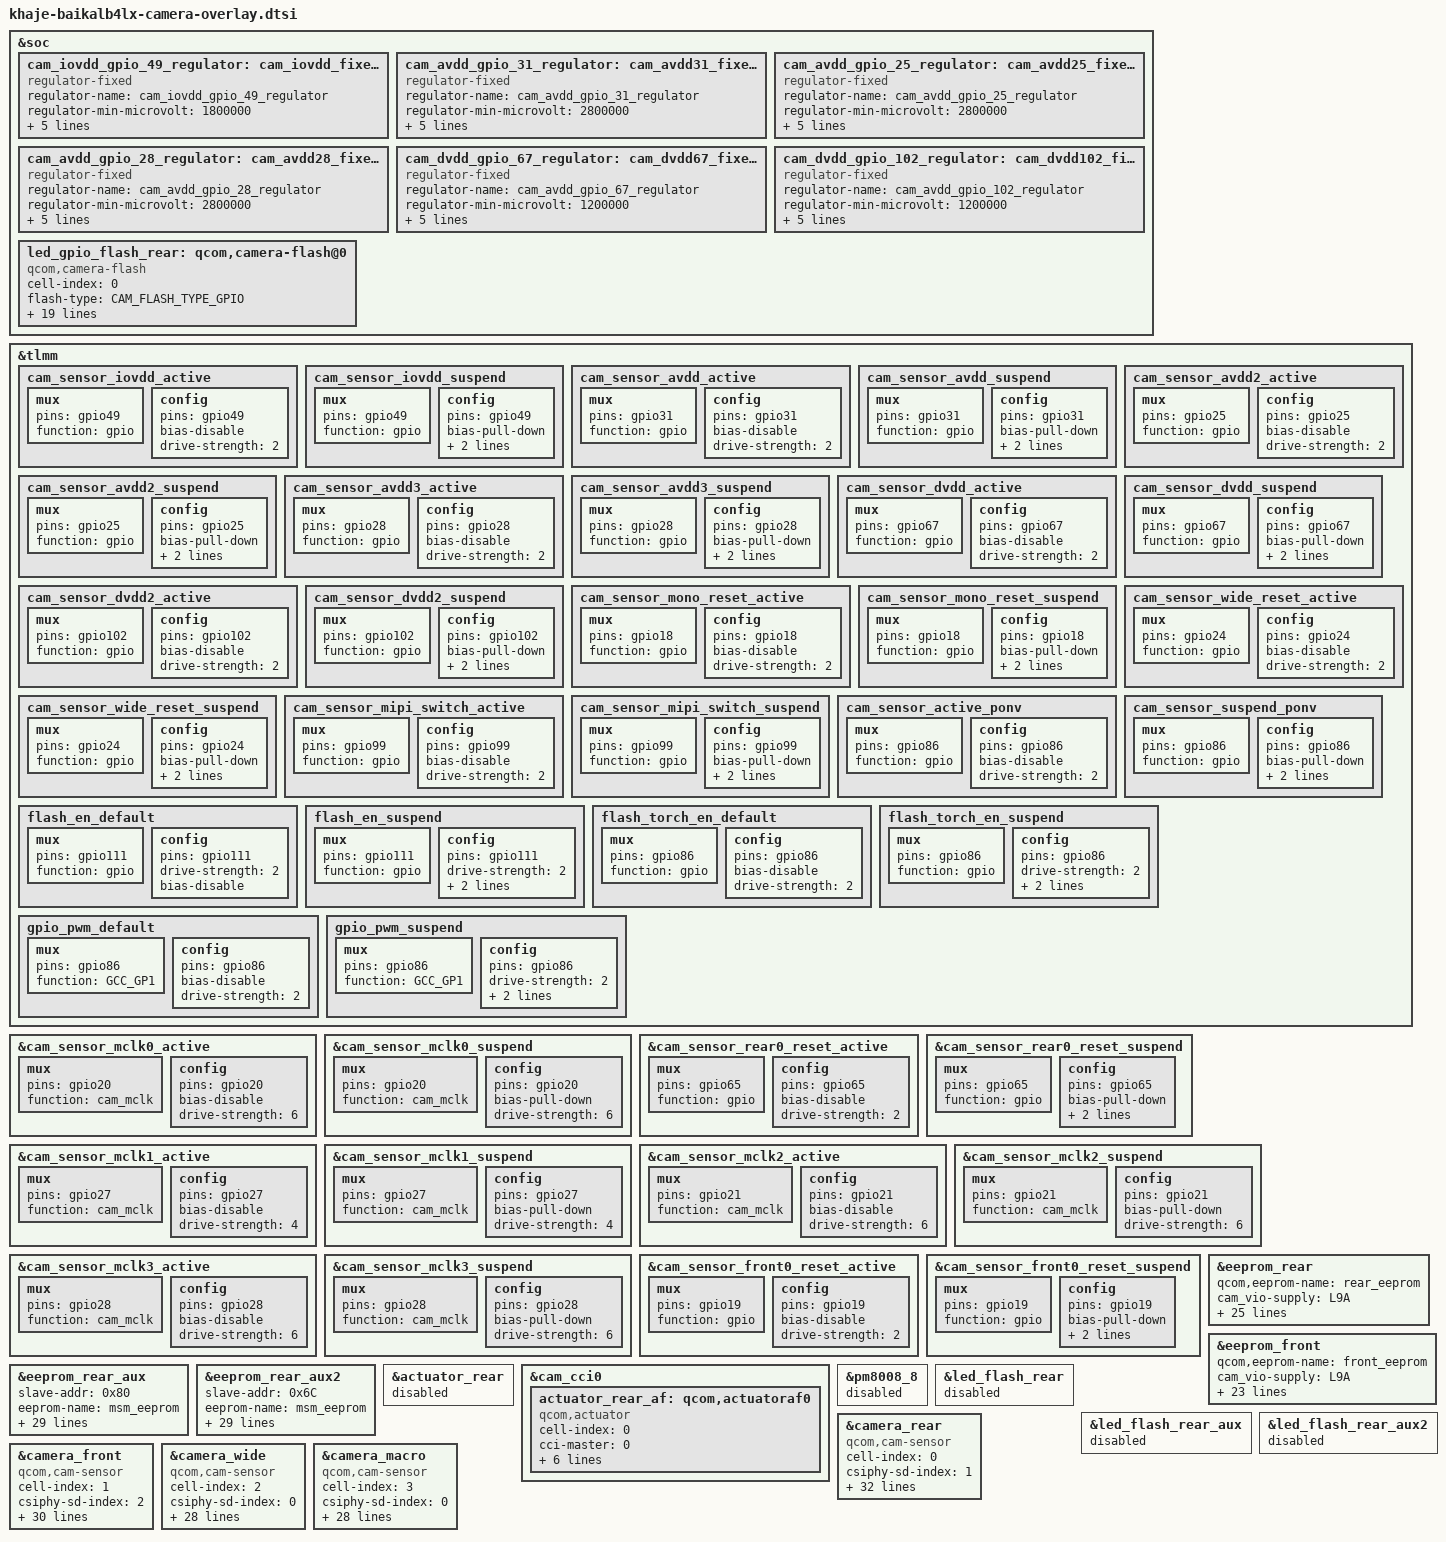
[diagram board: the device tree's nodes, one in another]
//khaje-camera-sensor-qrd.dtsi

&soc {
    cam_iovdd_gpio_49_regulator:cam_iovdd_fixed_regulator {
        compatible = "regulator-fixed";
        regulator-name = "cam_iovdd_gpio_49_regulator";
        regulator-min-microvolt = <1800000>;
        regulator-max-microvolt = <1800000>;
        enable-active-high;
        gpio = <&tlmm 49 0>;
        pinctrl-names = "cam_default","cam_suspend";
        pinctrl-0 = <&cam_sensor_iovdd_active>;
        pinctrl-1 = <&cam_sensor_iovdd_suspend>;
    };
    cam_avdd_gpio_31_regulator:cam_avdd31_fixed_regulator {
        compatible = "regulator-fixed";
        regulator-name = "cam_avdd_gpio_31_regulator";
        regulator-min-microvolt = <2800000>;
        regulator-max-microvolt = <2800000>;
        enable-active-high;
        gpio = <&tlmm 31 0>;
        pinctrl-names = "cam_default","cam_suspend";
        pinctrl-0 = <&cam_sensor_avdd_active>;
        pinctrl-1 = <&cam_sensor_avdd_suspend>;
    };
    cam_avdd_gpio_25_regulator:cam_avdd25_fixed_regulator {
        compatible = "regulator-fixed";
        regulator-name = "cam_avdd_gpio_25_regulator";
        regulator-min-microvolt = <2800000>;
        regulator-max-microvolt = <2800000>;
        enable-active-high;
        gpio = <&tlmm 25 0>;
        pinctrl-names = "cam_default","cam_suspend";
        pinctrl-0 = <&cam_sensor_avdd2_active>;
        pinctrl-1 = <&cam_sensor_avdd2_suspend>;
    };
    cam_avdd_gpio_28_regulator:cam_avdd28_fixed_regulator {
        compatible = "regulator-fixed";
        regulator-name = "cam_avdd_gpio_28_regulator";
        regulator-min-microvolt = <2800000>;
        regulator-max-microvolt = <2800000>;
        enable-active-high;
        gpio = <&tlmm 28 0>;
        pinctrl-names = "cam_default","cam_suspend";
        pinctrl-0 = <&cam_sensor_avdd3_active>;
        pinctrl-1 = <&cam_sensor_avdd3_suspend>;
    };
    cam_dvdd_gpio_67_regulator:cam_dvdd67_fixed_regulator {
        compatible = "regulator-fixed";
        regulator-name = "cam_avdd_gpio_67_regulator";
        regulator-min-microvolt = <1200000>;
        regulator-max-microvolt = <1200000>;
        enable-active-high;
        gpio = <&tlmm 67 0>;
        pinctrl-names = "cam_default","cam_suspend";
        pinctrl-0 = <&cam_sensor_dvdd_active>;
        pinctrl-1 = <&cam_sensor_dvdd_suspend>;
    };
    cam_dvdd_gpio_102_regulator:cam_dvdd102_fixed_regulator {
        compatible = "regulator-fixed";
        regulator-name = "cam_avdd_gpio_102_regulator";
        regulator-min-microvolt = <1200000>;
        regulator-max-microvolt = <1200000>;
        enable-active-high;
        gpio = <&tlmm 102 0>;
        pinctrl-names = "cam_default","cam_suspend";
        pinctrl-0 = <&cam_sensor_dvdd2_active>;
        pinctrl-1 = <&cam_sensor_dvdd2_suspend>;
    };
};

&tlmm {

    cam_sensor_iovdd_active: cam_sensor_iovdd_active {
        mux {
            pins = "gpio49";
            function = "gpio";
        };
        config {
            pins = "gpio49";
            bias-disable; /* No PULL */
            drive-strength = <2>; /* 2 MA */
        };
    };
    cam_sensor_iovdd_suspend: cam_sensor_iovdd_suspend {
        mux {
            pins = "gpio49";
            function = "gpio";
        };
        config {
            pins = "gpio49";
            bias-pull-down; /* PULL DOWN */
            drive-strength = <2>; /* 2 MA */
            output-low;
        };
    };
    cam_sensor_avdd_active: cam_sensor_avdd_active {
        mux {
            pins = "gpio31";
            function = "gpio";
        };
        config {
            pins = "gpio31";
            bias-disable; /* No PULL */
            drive-strength = <2>; /* 2 MA */
        };
    };
    cam_sensor_avdd_suspend: cam_sensor_avdd_suspend {
        mux {
            pins = "gpio31";
            function = "gpio";
        };
        config {
            pins = "gpio31";
            bias-pull-down; /* PULL DOWN */
            drive-strength = <2>; /* 2 MA */
            output-low;
        };
    };
    cam_sensor_avdd2_active: cam_sensor_avdd2_active {
        mux {
            pins = "gpio25";
            function = "gpio";
        };
        config {
            pins = "gpio25";
            bias-disable; /* No PULL */
            drive-strength = <2>; /* 2 MA */
        };
    };
    cam_sensor_avdd2_suspend: cam_sensor_avdd2_suspend {
        mux {
            pins = "gpio25";
            function = "gpio";
        };
        config {
            pins = "gpio25";
            bias-pull-down; /* PULL DOWN */
            drive-strength = <2>; /* 2 MA */
            output-low;
        };
    };
    cam_sensor_avdd3_active: cam_sensor_avdd3_active {
        mux {
            pins = "gpio28";
            function = "gpio";
        };
        config {
            pins = "gpio28";
            bias-disable; /* No PULL */
            drive-strength = <2>; /* 2 MA */
        };
    };
    cam_sensor_avdd3_suspend: cam_sensor_avdd3_suspend {
        mux {
            pins = "gpio28";
            function = "gpio";
        };
        config {
            pins = "gpio28";
            bias-pull-down; /* PULL DOWN */
            drive-strength = <2>; /* 2 MA */
            output-low;
        };
    };
    cam_sensor_dvdd_active: cam_sensor_dvdd_active {
        mux {
            pins = "gpio67";
            function = "gpio";
        };
        config {
            pins = "gpio67";
            bias-disable; /* No PULL */
            drive-strength = <2>; /* 2 MA */
        };
    };
    cam_sensor_dvdd_suspend: cam_sensor_dvdd_suspend {
        mux {
            pins = "gpio67";
            function = "gpio";
        };
        config {
            pins = "gpio67";
            bias-pull-down; /* PULL DOWN */
            drive-strength = <2>; /* 2 MA */
            output-low;
        };
    };
    cam_sensor_dvdd2_active: cam_sensor_dvdd2_active {
        mux {
            pins = "gpio102";
            function = "gpio";
        };
        config {
            pins = "gpio102";
            bias-disable; /* No PULL */
            drive-strength = <2>; /* 2 MA */
        };
    };
    cam_sensor_dvdd2_suspend: cam_sensor_dvdd2_suspend {
        mux {
            pins = "gpio102";
            function = "gpio";
        };
        config {
            pins = "gpio102";
            bias-pull-down; /* PULL DOWN */
            drive-strength = <2>; /* 2 MA */
            output-low;
        };
    };
    cam_sensor_mono_reset_active: cam_sensor_mono_reset_active {
        mux {
            pins = "gpio18";
            function = "gpio";
        };
        config {
            pins = "gpio18";
            bias-disable; /* No PULL */
            drive-strength = <2>; /* 2 MA */
        };
    };
    cam_sensor_mono_reset_suspend: cam_sensor_mono_reset_suspend {
        mux {
            pins = "gpio18";
            function = "gpio";
        };
        config {
            pins = "gpio18";
            bias-pull-down; /* PULL DOWN */
            drive-strength = <2>; /* 2 MA */
            output-low;
        };
    };

    cam_sensor_wide_reset_active: cam_sensor_wide_reset_active {
        mux {
            pins = "gpio24";
            function = "gpio";
        };
        config {
            pins = "gpio24";
            bias-disable; /* No PULL */
            drive-strength = <2>; /* 2 MA */
        };
    };
    cam_sensor_wide_reset_suspend: cam_sensor_wide_reset_suspend {
        mux {
            pins = "gpio24";
            function = "gpio";
        };
        config {
            pins = "gpio24";
            bias-pull-down; /* PULL DOWN */
            drive-strength = <2>; /* 2 MA */
            output-low;
        };
    };
    cam_sensor_mipi_switch_active: cam_sensor_mipi_switch_active {
        mux {
            pins = "gpio99";
            function = "gpio";
        };
        config {
            pins = "gpio99";
            bias-disable; /* No PULL */
            drive-strength = <2>; /* 2 MA */
        };
    };
    cam_sensor_mipi_switch_suspend: cam_sensor_mipi_switch_suspend {
        mux {
            pins = "gpio99";
            function = "gpio";
        };
        config {
            pins = "gpio99";
            bias-pull-down; /* PULL DOWN */
            drive-strength = <2>; /* 2 MA */
            output-low;
        };
    };
    cam_sensor_active_ponv: cam_sensor_active_ponv {
        /* ponv */
        mux {
            pins = "gpio86";
            function = "gpio";
        };

        config {
            pins = "gpio86";
            bias-disable;  /* NO PULL */
            drive-strength = <2>; /* 2 MA */
            /*output-high;*/
        };
    };

    cam_sensor_suspend_ponv: cam_sensor_suspend_ponv {
        /* PONV */
        mux {
            pins = "gpio86";
            function = "gpio";
        };

        config {
            pins = "gpio86";
            bias-pull-down; /* PULL DOWN */
            drive-strength = <2>; /* 2 MA */
            output-low;
        };
    };
    flash_en_default: flash_en_default {
         mux {
             pins = "gpio111";
             function = "gpio";
         };
         config {
             pins = "gpio111";
             drive-strength = <2>;
             bias-disable; /* No PULL */
         };
     };
     flash_en_suspend: flash_en_suspend {
         mux {
             pins = "gpio111";
             function = "gpio";
         };
         config {
             pins = "gpio111";
             drive-strength = <2>;
             bias-pull-down;
             output-low;
         };
     };
     flash_torch_en_default: flash_torch_en_default {
         mux {
             pins = "gpio86";
             function = "gpio";
         };
         config {
             pins = "gpio86";
             bias-disable; /* No PULL */
             drive-strength = <2>;
         };
     };
     flash_torch_en_suspend: flash_torch_en_suspend {
         mux {
             pins = "gpio86";
             function = "gpio";
         };
         config {
             pins = "gpio86";
             drive-strength = <2>;
             bias-pull-down;
             output-low;
         };
     };
     gpio_pwm_default: gpio_pwm_default {
         mux {
             pins = "gpio86";
             function = "GCC_GP1";
         };

         config {
             pins = "gpio86";
             bias-disable; /* No PULL */
             drive-strength = <2>;
         };
     };
     gpio_pwm_suspend: gpio_pwm_suspend {
         mux {
             pins = "gpio86";
             function = "GCC_GP1";
         };

         config {
             pins = "gpio86";
             drive-strength = <2>;
             bias-pull-down;
             output-low;
         };
     };
};

&cam_sensor_mclk0_active {
    /* MCLK 0*/
    mux {
        pins = "gpio20";
        function = "cam_mclk";
    };

    config {
        pins = "gpio20";
        bias-disable; /* No PULL */
        drive-strength = <6>; /* 2 MA */
    };
};

&cam_sensor_mclk0_suspend {
    /* MCLK 0*/
    mux {
        pins = "gpio20";
        function = "cam_mclk";
    };

    config {
        pins = "gpio20";
        bias-pull-down; /* PULL DOWN */
        drive-strength = <6>; /* 2 MA */
    };
};

&cam_sensor_rear0_reset_active {
    mux {
        pins = "gpio65";
        function = "gpio";
    };
    config {
        pins = "gpio65";
        bias-disable; /* No PULL */
        drive-strength = <2>; /* 2 MA */
    };
};

&cam_sensor_rear0_reset_suspend {
    mux {
        pins = "gpio65";
        function = "gpio";
    };
    config {
        pins = "gpio65";
        bias-pull-down; /* PULL DOWN */
        drive-strength = <2>; /* 2 MA */
        output-low;
    };
};

&cam_sensor_mclk1_active {
    /* MCLK 1*/
    mux {
        pins = "gpio27";
        function = "cam_mclk";
    };

    config {
        pins = "gpio27";
        bias-disable; /* No PULL */
        drive-strength = <4>; /* 4 MA */
    };
};
&cam_sensor_mclk1_suspend {
    /* MCLK 1*/
    mux {
        pins = "gpio27";
        function = "cam_mclk";
    };

    config {
        pins = "gpio27";
        bias-pull-down; /* PULL DOWN */
        drive-strength = <4>; /* 4 MA */
    };
};

&cam_sensor_mclk2_active {
    /* MCLK 2*/
    mux {
        pins = "gpio21";
        function = "cam_mclk";
    };

    config {
        pins = "gpio21";
        bias-disable; /* No PULL */
        drive-strength = <6>; /* 2 MA */
    };
};

&cam_sensor_mclk2_suspend {
    /* MCLK 2*/
    mux {
        pins = "gpio21";
        function = "cam_mclk";
    };

    config {
        pins = "gpio21";
        bias-pull-down; /* PULL DOWN */
        drive-strength = <6>; /* 2 MA */
    };
};

&cam_sensor_mclk3_active {
    /* MCLK 3*/
    mux {
        pins = "gpio28";
        function = "cam_mclk";
    };

    config {
        pins = "gpio28";
        bias-disable; /* No PULL */
        drive-strength = <6>; /* 2 MA */
    };
};

&cam_sensor_mclk3_suspend {
    /* MCLK 3*/
    mux {
        pins = "gpio28";
        function = "cam_mclk";
    };

    config {
        pins = "gpio28";
        bias-pull-down; /* PULL DOWN */
        drive-strength = <6>; /* 2 MA */
    };
};

&cam_sensor_front0_reset_active {
    mux {
        pins = "gpio19";
        function = "gpio";
    };
    config {
        pins = "gpio19";
        bias-disable; /* No PULL */
        drive-strength = <2>; /* 2 MA */
    };
};

&cam_sensor_front0_reset_suspend {
    mux {
        pins = "gpio19";
        function = "gpio";
    };
    config {
        pins = "gpio19";
        bias-pull-down; /* PULL DOWN */
        drive-strength = <2>; /* 2 MA */
        output-low;
    };
};

&eeprom_rear {
        qcom,eeprom-name = "rear_eeprom";
        cam_vio-supply = <&L9A>;
        cam_clk-supply = <&gcc_camss_top_gdsc>;
        cam_vana-supply = <&cam_avdd_gpio_25_regulator>;
        cam_vdig-supply = <&cam_dvdd_gpio_67_regulator>;
        regulator-names = "cam_vio","cam_clk","cam_vana","cam_vdig";
        rgltr-cntrl-support;
        pwm-switch;
        rgltr-min-voltage = <1800000 0 2800000 1200000>;
        rgltr-max-voltage = <1800000 0 2800000 1200000>;
        rgltr-load-current = <120000 0 120000 120000>;
        gpio-no-mux = <0>;
        pinctrl-names = "cam_default", "cam_suspend";
        pinctrl-0 = <&cam_sensor_mclk0_active
                     &cam_sensor_rear0_reset_active>;
        pinctrl-1 = <&cam_sensor_mclk0_suspend
                     &cam_sensor_rear0_reset_suspend>;
        gpios = <&tlmm 20 0>,
                <&tlmm 65 0>;
        gpio-reset = <1>;
        gpio-req-tbl-num = <0 1>;
        gpio-req-tbl-flags = <1 0>;
        gpio-req-tbl-label = "CAMIF_MCLK0",
                             "CAM_RESET0";
        sensor-mode = <0>;
        cci-master = <0>;
        status = "ok";
        clocks = <&gcc GCC_CAMSS_MCLK0_CLK>;
        clock-names = "cam_clk";
        clock-cntl-level = "turbo";
        clock-rates = <24000000>;
};

&eeprom_front {
        qcom,eeprom-name = "front_eeprom";
        cam_vio-supply = <&L9A>;
        cam_clk-supply = <&gcc_camss_top_gdsc>;
        cam_vana-supply = <&cam_avdd_gpio_25_regulator>;
        cam_vdig-supply = <&cam_dvdd_gpio_67_regulator>;
        regulator-names = "cam_vio","cam_clk","cam_vana","cam_vdig";
        rgltr-cntrl-support;
        pwm-switch;
        rgltr-min-voltage = <1800000 0 2800000 1200000>;
        rgltr-max-voltage = <1800000 0 2800000 1200000>;
        rgltr-load-current = <120000 0 120000 120000>;
        gpio-no-mux = <0>;
        pinctrl-names = "cam_default", "cam_suspend";
        pinctrl-0 = <&cam_sensor_mclk2_active
                     &cam_sensor_front0_reset_active>;
        pinctrl-1 = <&cam_sensor_mclk2_suspend
                     &cam_sensor_front0_reset_suspend>;
        gpios = <&tlmm 21 0>,
                <&tlmm 19 0>;
        gpio-reset = <1>;
        gpio-req-tbl-num = <0 1>;
        gpio-req-tbl-flags = <1 0>;
        gpio-req-tbl-label = "CAMIF_MCLK1",
                                "CAM_RESET1";
        cci-master = <1>;
        clocks = <&gcc GCC_CAMSS_MCLK1_CLK>;
        clock-rates = <24000000>;
};

&eeprom_rear_aux {
        slave-addr = <0x80>;
        eeprom-name = "msm_eeprom";
        i2c-freq-mode = <1>;
        cam_vio-supply = <&L9A>;
        cam_clk-supply = <&gcc_camss_top_gdsc>;
        cam_vana-supply = <&cam_avdd_gpio_25_regulator>;
        regulator-names = "cam_vio","cam_clk","cam_vana";
        rgltr-cntrl-support;
        pwm-switch;
        rgltr-min-voltage = <1800000 0 2800000>;
        rgltr-max-voltage = <1800000 0 2800000>;
        rgltr-load-current = <120000 0 120000>;
        gpio-no-mux = <0>;
        pinctrl-names = "cam_default", "cam_suspend";
        qcom,cam-power-seq-type = "cam_vio", "cam_vana", "cam_clk";
        qcom,cam-power-seq-cfg-val = <1 1 24000000>;
        qcom,cam-power-seq-delay = <1 1 5>;
        pinctrl-0 = <&cam_sensor_mclk1_active
                     &cam_sensor_mono_reset_active>;
        pinctrl-1 = <&cam_sensor_mclk1_suspend
                     &cam_sensor_mono_reset_suspend>;
        gpios = <&tlmm 27 0>,
                <&tlmm 18 0>;
        gpio-reset = <1>;
        gpio-req-tbl-num = <0 1>;
        gpio-req-tbl-flags = <1 0>;
        gpio-req-tbl-label = "CAMIF_MCLK2",
                                "CAM_RESET2";
        sensor-mode = <0>;
        cci-master = <1>;
        status = "ok";
        clocks = <&gcc GCC_CAMSS_MCLK2_CLK>;
        clock-names = "cam_clk";
        clock-cntl-level = "turbo";
        clock-rates = <24000000>;
};

&eeprom_rear_aux2 {
    slave-addr = <0x6C>;
    eeprom-name = "msm_eeprom";
    i2c-freq-mode = <1>;
    cam_vio-supply = <&L9A>;
    cam_clk-supply = <&gcc_camss_top_gdsc>;
    cam_vana-supply = <&cam_avdd_gpio_25_regulator>;
    regulator-names = "cam_vio","cam_clk","cam_vana";
    rgltr-cntrl-support;
    pwm-switch;
    rgltr-min-voltage = <1800000 0 2800000>;
    rgltr-max-voltage = <1800000 0 2800000>;
    rgltr-load-current = <120000 0 120000>;
    gpio-no-mux = <0>;
    pinctrl-names = "cam_default", "cam_suspend";
    qcom,cam-power-seq-type = "cam_reset", "cam_vio", "cam_vana", "cam_reset", "cam_clk";
    qcom,cam-power-seq-cfg-val = <0 1 1 1 24000000>;
    qcom,cam-power-seq-delay = <1 1 1 1 5>;
    pinctrl-0 = <&cam_sensor_mclk1_active
                 &cam_sensor_mono_reset_active>;
    pinctrl-1 = <&cam_sensor_mclk1_suspend
                 &cam_sensor_mono_reset_suspend>;
    gpios = <&tlmm 27 0>,
            <&tlmm 18 0>;
    gpio-reset = <1>;
    gpio-req-tbl-num = <0 1>;
    gpio-req-tbl-flags = <1 0>;
    gpio-req-tbl-label = "CAMIF_MCLK2",
                            "CAM_RESET2";
    sensor-mode = <0>;
    cci-master = <1>;
    status = "ok";
    clocks = <&gcc GCC_CAMSS_MCLK2_CLK>;
    clock-names = "cam_clk";
    clock-cntl-level = "turbo";
    clock-rates = <24000000>;
};

&actuator_rear {
    status = "disable";
};

&soc {
        led_gpio_flash_rear: qcom,camera-flash@0 {
                cell-index = <0>;
                compatible = "qcom,camera-flash";
                flash-type = <CAM_FLASH_TYPE_GPIO>;
                gpio-no-mux = <0>;
                flash-name = "sgm3785";
                pinctrl-names = "cam_default", "cam_suspend","pwm_default","pwm_suspend";
                pinctrl-0 = <&flash_en_default &flash_torch_en_default>;
                pinctrl-1 = <&flash_en_suspend &flash_torch_en_suspend>;
                pinctrl-2 = <&gpio_pwm_default>;
                pinctrl-3 = <&gpio_pwm_suspend>;
                gpios = <&tlmm 111 0>,
                        <&tlmm 86 0>;
                gpio-custom1 = <0>;
                gpio-custom2 = <1>;
                gpio-req-tbl-num = <0 1>;
                gpio-req-tbl-flags = <0 0>;
                gpio-req-tbl-label = "CUSTOM_GPIO1","CUSTOM_GPIO2";
                flash-current = <1075>;
                torch-current = <160>;
                clocks = <&gcc GCC_GP1_CLK>;
                clock-names = "gpio-pwm-clk";
                clock-cntl-level = "turbo";
                clock-rates = <48000>;
                status = "ok";
        };
};

&cam_cci0 {
        actuator_rear_af: qcom,actuatoraf0 {
                cell-index = <0>;
                compatible = "qcom,actuator";
                cci-master = <0>;
                cam_vaf-supply = <&cam_avdd_gpio_28_regulator>;
                regulator-names = "cam_vaf";
                rgltr-cntrl-support;
                rgltr-min-voltage = <2800000>;
                rgltr-max-voltage = <2800000>;
                rgltr-load-current = <100000>;
                status = "ok";
        };
};

&pm8008_8 {
	status = "disabled";
};

&led_flash_rear {
	status = "disabled";
};

&led_flash_rear_aux{
    status = "disabled";
};
&led_flash_rear_aux2{
    status = "disabled";
};
&camera_rear {
        cell-index = <0>;
        compatible = "qcom,cam-sensor";
        csiphy-sd-index = <1>;
        sensor-position-roll = <90>;
        sensor-position-pitch = <0>;
        sensor-position-yaw = <180>;
        actuator-src = <&actuator_rear_af>;
        led-flash-src = <&led_gpio_flash_rear>;
        eeprom-src = <&eeprom_rear>;
        cam_vio-supply = <&L9A>;
        cam_clk-supply = <&gcc_camss_top_gdsc>;
        cam_vana-supply = <&cam_avdd_gpio_25_regulator>;
        cam_vdig-supply = <&cam_dvdd_gpio_67_regulator>;
        regulator-names = "cam_vio","cam_clk","cam_vana","cam_vdig";
        rgltr-cntrl-support;
        pwm-switch;
        rgltr-min-voltage = <1800000 0 2800000 1200000>;
        rgltr-max-voltage = <1800000 0 2800000 1200000>;
        rgltr-load-current = <120000 0 120000 120000>;
        gpio-no-mux = <0>;
        pinctrl-names = "cam_default", "cam_suspend";
        pinctrl-0 = <&cam_sensor_mclk0_active
                     &cam_sensor_rear0_reset_active>;
        pinctrl-1 = <&cam_sensor_mclk0_suspend
                     &cam_sensor_rear0_reset_suspend>;
        gpios = <&tlmm 20 0>,
                <&tlmm 65 0>;
        gpio-reset = <1>;
        gpio-req-tbl-num = <0 1>;
        gpio-req-tbl-flags = <1 0>;
        gpio-req-tbl-label = "CAMIF_MCLK0",
                             "CAM_RESET0";
        sensor-mode = <0>;
        cci-master = <0>;
        status = "ok";
        clocks = <&gcc GCC_CAMSS_MCLK0_CLK>;
        clock-names = "cam_clk";
        clock-cntl-level = "turbo";
        clock-rates = <24000000>;
};

&camera_front {
        cell-index = <1>;
        compatible = "qcom,cam-sensor";
        csiphy-sd-index = <2>;
        sensor-position-roll = <270>;
        sensor-position-pitch = <0>;
        sensor-position-yaw = <0>;
        eeprom-src = <&eeprom_front>;
        cam_vio-supply = <&L9A>;
        cam_clk-supply = <&gcc_camss_top_gdsc>;
        cam_vana-supply = <&cam_avdd_gpio_25_regulator>;
        cam_vdig-supply = <&cam_dvdd_gpio_67_regulator>;
        regulator-names = "cam_vio","cam_clk","cam_vana","cam_vdig";
        rgltr-cntrl-support;
        pwm-switch;
        rgltr-min-voltage = <1800000 0 2800000 1200000>;
        rgltr-max-voltage = <1800000 0 2800000 1200000>;
        rgltr-load-current = <120000 0 120000 120000>;
        gpio-no-mux = <0>;
        pinctrl-names = "cam_default", "cam_suspend";
        pinctrl-0 = <&cam_sensor_mclk2_active
                     &cam_sensor_front0_reset_active>;
        pinctrl-1 = <&cam_sensor_mclk2_suspend
                     &cam_sensor_front0_reset_suspend>;
        gpios = <&tlmm 21 0>,
                <&tlmm 19 0>;
        gpio-reset = <1>;
        gpio-req-tbl-num = <0 1>;
        gpio-req-tbl-flags = <1 0>;
        gpio-req-tbl-label = "CAMIF_MCLK1",
                                "CAM_RESET1";
        sensor-mode = <0>;
        cci-master = <1>;
        status = "ok";
        clocks = <&gcc GCC_CAMSS_MCLK1_CLK>;
        clock-names = "cam_clk";
        clock-cntl-level = "turbo";
        clock-rates = <24000000>;
};

// qvga
&camera_wide {
        cell-index = <2>;
        compatible = "qcom,cam-sensor";
        csiphy-sd-index = <0>;
        sensor-position-roll = <270>;
        sensor-position-pitch = <0>;
        sensor-position-yaw = <180>;
        eeprom-src = <&eeprom_rear_aux>;
        cam_vio-supply = <&L9A>;
        cam_clk-supply = <&gcc_camss_top_gdsc>;
        cam_vana-supply = <&cam_avdd_gpio_25_regulator>;
        regulator-names = "cam_vio","cam_clk","cam_vana";
        rgltr-cntrl-support;
        pwm-switch;
        rgltr-min-voltage = <1800000 0 2800000>;
        rgltr-max-voltage = <1800000 0 2800000>;
        rgltr-load-current = <120000 0 120000>;
        gpio-no-mux = <0>;
        pinctrl-names = "cam_default", "cam_suspend";
        pinctrl-0 = <&cam_sensor_mclk1_active
                     &cam_sensor_mono_reset_active>;
        pinctrl-1 = <&cam_sensor_mclk1_suspend
                     &cam_sensor_mono_reset_suspend>;
        gpios = <&tlmm 27 0>,
                <&tlmm 18 0>;
        gpio-reset = <1>;
        gpio-req-tbl-num = <0 1>;
        gpio-req-tbl-flags = <1 0>;
        gpio-req-tbl-label = "CAMIF_MCLK2",
                                "CAM_RESET2";
        sensor-mode = <0>;
        cci-master = <1>;
        status = "ok";
        clocks = <&gcc GCC_CAMSS_MCLK2_CLK>;
        clock-names = "cam_clk";
        clock-cntl-level = "turbo";
        clock-rates = <24000000>;
};

// qvga2
&camera_macro {
        cell-index = <3>;
        compatible = "qcom,cam-sensor";
        csiphy-sd-index = <0>;
        sensor-position-roll = <270>;
        sensor-position-pitch = <0>;
        sensor-position-yaw = <180>;
        eeprom-src = <&eeprom_rear_aux2>;
        cam_vio-supply = <&L9A>;
        cam_clk-supply = <&gcc_camss_top_gdsc>;
        cam_vana-supply = <&cam_avdd_gpio_25_regulator>;
        regulator-names = "cam_vio","cam_clk","cam_vana";
        rgltr-cntrl-support;
        pwm-switch;
        rgltr-min-voltage = <1800000 0 2800000>;
        rgltr-max-voltage = <1800000 0 2800000>;
        rgltr-load-current = <120000 0 120000>;
        gpio-no-mux = <0>;
        pinctrl-names = "cam_default", "cam_suspend";
        pinctrl-0 = <&cam_sensor_mclk1_active
                     &cam_sensor_mono_reset_active>;
        pinctrl-1 = <&cam_sensor_mclk1_suspend
                     &cam_sensor_mono_reset_suspend>;
        gpios = <&tlmm 27 0>,
                <&tlmm 18 0>;
        gpio-reset = <1>;
        gpio-req-tbl-num = <0 1>;
        gpio-req-tbl-flags = <1 0>;
        gpio-req-tbl-label = "CAMIF_MCLK2",
                                "CAM_RESET2";
        sensor-mode = <0>;
        cci-master = <1>;
        status = "ok";
        clocks = <&gcc GCC_CAMSS_MCLK2_CLK>;
        clock-names = "cam_clk";
        clock-cntl-level = "turbo";
        clock-rates = <24000000>;
};
